# ET6801 register map
Vendor: ETMCU Inc.; File version: v0.0.1
CPU: CM7 r2p1, little endian, MPU, FPU, I-cache, D-cache, ITCM, DTCM, 4 interrupt priority bits
Registers are 32-bit, read-write, reset 0x0 unless marked. A register's access mark holds for its fields unless they carry their own. Offsets are from the block's base; [hi:lo] are bit positions.

## DAC0 — Provide an overview of the purpose and functionality of the peripheral: dacc_cfg
Base 0x40100000
Same registers: DAC1 0x40101000
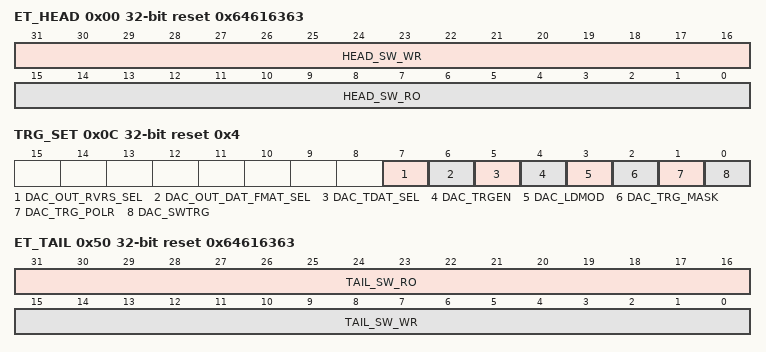
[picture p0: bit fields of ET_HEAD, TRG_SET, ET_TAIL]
0x00 ET_HEAD reset 0x64616363
  [31:16] HEAD_SW_WR — 软件测试读写寄存器，硬件无访问
  [15:0] HEAD_SW_RO ro — 软件只读上报寄存器，硬件无访问，dacc的ASICII 码表示
0x04 TDAT
  [11:0] DAC_TDAT — DAC发送数据寄存器，支持DMA更新
0x08 TRG_SEL
  [2:0] DAC_TRG_SEL — 触发启动源选择寄存器 'd0: 触发启动源选择SW配置; 'd1 : 触发启动源选择sTimer; 'd2 : 触发启动源选择eTimer; 'd3 : 触发启动源选择SuperPWM; 'd4 : 触发启动源选择tx down event; 'd5 : 未使用，接0; 'd6: 未使用，接0; 'd7 : 触发启动源选择DMA搬移完成; 默认为0，触发启动源选择SW配置。
0x0C TRG_SET reset 0x4
  [7] DAC_OUT_RVRS_SEL — dac输出数据反向选择 'd0:dac输出数据不反向，默认值； 'd1: dac输出数据反向；
  [6] DAC_OUT_DAT_FMAT_SEL — dac输出数据格式选择 'd0:偏移码输出，默认值； 'd1:补码输出；
  [5] DAC_TDAT_SEL — DAC发送数据寄存器 'd0: DAC选择从cfg_dac_tdat位域发送数据，默认值； 'd1:DAC选择从输入数据端口发送数据；
  [4] DAC_TRGEN — DAC发波启动使能控制信号寄存器 0：DAC发波不使能； 1：DAC发波使能；
  [3] DAC_LDMOD — 加载模式选择寄存器
  [2] DAC_TRG_MASK — 触发源屏蔽寄存器
  [1] DAC_TRG_POLR — 触发源极性取反寄存器
  [0] DAC_SWTRG — 软件触发寄存器，软件配置的触发源，自清0
0x10 TRG_DLY
  [7:0] DAC_TRG_DLY — 触发启动延迟寄存器，对输入的触发启动信号延迟，输出到波形产生模块。
0x14 TRG_REPT_RPT
  [0] TRG_REPT_RPT — 触发重复告警寄存器，软件写1清
0x18 TXDN_RPT
  [0] DAC_TXDN_RPT — 发波结束上报寄存器，软件写1清 注：在cfg_dac_tdat_sel =1时，即数据源来源于dacc的输入端口时，内部的数据伴随时钟将常为高，该上报寄存器也一直为1。
0x1C TXDN_REPT_RPT
  [0] DAC_TXDN_REPT_RPT — 发波结束重复脉冲告警寄存器，软件写1清 注：在cfg_dac_tdat_sel =1时，即数据源来源于dacc的输入端口时，内部的数据伴随时钟将常为高，该上报寄存器也一直为1。
0x20 TDAT ro
  [11:0] TDAT_LOAD_RPT — dac load数据上报
0x24 OS_ADJ
  [12:0] DAC_OS_ADJ — 直流失配调整寄存器
0x28 GAIN_ADJ reset 0x400
  [10:0] DAC_GAIN_ADJ — 增益误差调整寄存器
0x2C INT_MASK
  [0] DAC_INT_MASK — 中断屏蔽信号
0x30 INT_EN
  [0] DAC_INT_EN — 中断源使能信号
0x34 INT_FORCE_IND
  [0] DAC_INT_FORCE_IND — 事件中断测试寄存器，自清0寄存器
0x38 INT_CLR
  [0] DAC_INT_CLR — 中断清除寄存器，自清0寄存器
0x3C INT_RAW_RPT ro
  [0] DAC_INT_RAW_RPT — DAC发送结束事件原始中断寄存器
0x40 INT_STATUS_RPT ro
  [0] DAC_INT_STATUS_RPT — DAC发送结束事件中断状态寄存器
0x44 HDSK_EN
  [0] DAC_HDSK_EN — DAC握手模块使能信号
0x48 DONE_WH reset 0xF
  [7:0] DAC_DONE_WH — DAC发送完成事件脉冲宽度。
0x4C DMAREQ_REPT_RPT
  [0] DAC_DMAREQ_REPT_RPT — DMA请求脉冲重复告警寄存器，软件写1清
0x50 ET_TAIL reset 0x64616363
  [31:16] TAIL_SW_RO ro — 软件只读硬件上报寄存器
  [15:0] TAIL_SW_WR — 软件测试读写寄存器，硬件无访问

## WAG — Provide an overview of the purpose and functionality of the peripheral: wag_cfg
Base 0x40103000
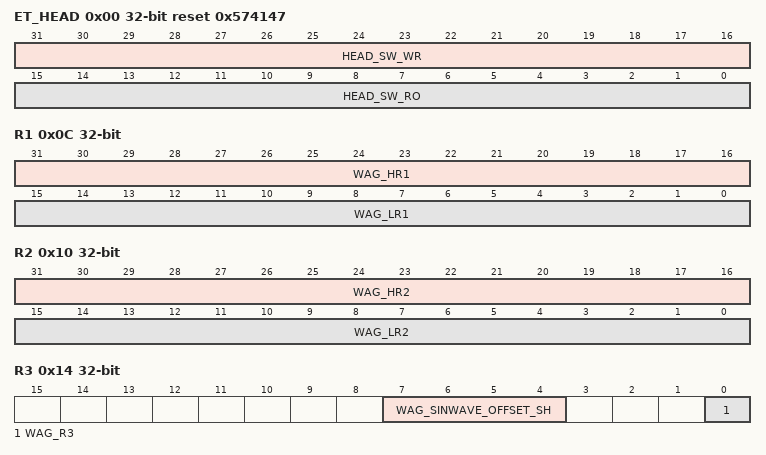
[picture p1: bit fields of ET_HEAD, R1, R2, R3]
0x00 ET_HEAD reset 0x574147
  [31:16] HEAD_SW_WR — 软件测试读写寄存器，硬件无访问
  [15:0] HEAD_SW_RO ro — 软件只读上报寄存器，硬件无访问,WAG的ASICII 码表示
0x04 CORDIC_CTRL0
  [8:4] CORDIC_NOI — CORDIC迭代周期数选择寄存器，周期数为配置值+1
0x08 R0
  [15:0] WAG_R0 — R0寄存器，触发延迟时间，使用预分频后时钟，延迟时间为：cfg_wag_r0个周期。
0x0C R1
  [31:16] WAG_HR1 — R1寄存器高16bit。 (1)RMAP波/三角波：上行幅度步进 (2)正弦波：频率控制字
  [15:0] WAG_LR1 — R1寄存器低16bit。 (1)RAMP波/三角波：下行幅度步进 (2)正弦波：初相
0x10 R2
  [31:16] WAG_HR2 — R2寄存器的高16bit (1)RMAP波/三角波：上门限值 (2)正弦波：直流幅度 (3)静态波/方波：值B
  [15:0] WAG_LR2 — R2寄存器的低16bit (1)RAMP波/三角波：下门限值 (2)正弦波：幅度调整量（仅支持1/2N幅度调整，N=0,...,12），幅度调整值需要提前除以缩放因子k，其中k为Cordic IP计算后产生的缩放因子，与计算精度相关，约为1.6 (3)静态波/方波：值A
0x14 R3
  [7:4] WAG_SINWAVE_OFFSET_SH — 正弦波幅度调整值m缩放量。即N的值
  [0] WAG_R3 — R3寄存器，用于指示R0~R2寄存器是否可加载。与cfg_wag_load_en配合使用。cfg_wag_load_en=1时，关注R3寄存器的值；当cfg_wag_load_en=0时，不关注R3寄存器的值 0x1：R0~R2已经准备好，可加载 0x0：R0~R2还未准备好，不可加载 硬件将R0~R2加载完成后，将该信号拉低 注：软件依次写入R0~R3，要将R3拉高，得先更新R0~R2
0x18 LOAD_EN reset 0x1
  [0] WAG_LOAD_EN — R0~R3是否一起加载 0x0：不要求R0~R2一致加载 0x1：要求R0~R2一致加载 注：动态寄存器，全局使能有效时可更改
0x1C RLOAD_MODE
  [0] WAG_RLOAD_MODE — R0~R3加载模式： 0x0：影子加载 0x1：立即加载 注：静态寄存器，全局使能有效时不可更改
0x20 EN
  [0] WAG_EN — 全局使能 0x0：使能 0x1：不使能
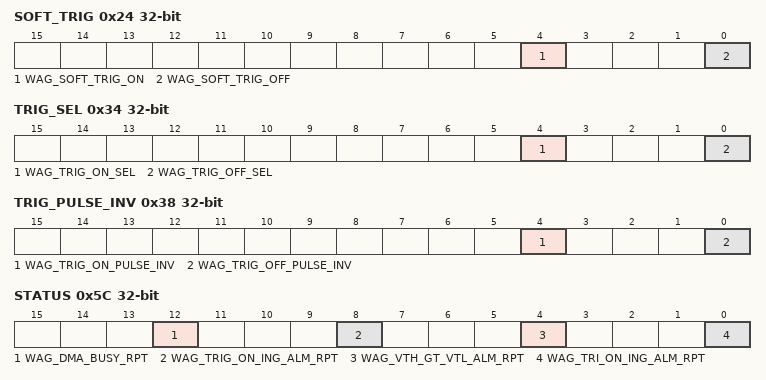
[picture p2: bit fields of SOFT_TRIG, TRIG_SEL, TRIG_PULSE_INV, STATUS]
0x24 SOFT_TRIG
  [4] WAG_SOFT_TRIG_ON — 软件启动触发 0x0：不触发 0x1：触发
  [0] WAG_SOFT_TRIG_OFF — 软件终止触发 0x0：不触发 0x1：触发
0x28 DATA_IN
  [15:0] WAG_DATA_IN — 软件保持功能模式下，软件配置码值专用寄存器 注：根据输出数据参数化位宽配置，如：输出位宽配置为12bit，则该值应该在0~4095取值
0x2C CLK_DIV_PARA reset 0xC7
  [15:0] WAG_CLK_DIV_PARA — 预分频系数，分频比为：cfg_wag_clk_div_para+1，单位为系统时钟周期 注：静态寄存器，全局使能有效时不可更改
0x30 HOLD_MODE_SEL
  [0] WAG_HOLD_MODE_SEL — 软件保持模式下，输出码值的选择 0x1：软件配置的专用寄存器码值 0x0：当前发波模式的即时值 注：静态寄存器，全局使能有效时不可更改
0x34 TRIG_SEL
  [4] WAG_TRIG_ON_SEL — 触发启动信号选择 0x0：软件触发 0x1：硬件触发 注：静态寄存器，全局使能有效时不可更改
  [0] WAG_TRIG_OFF_SEL — 触发终止信号选择 0x0：软件触发 0x1：硬件触发 注：静态寄存器，全局使能有效时不可更改
0x38 TRIG_PULSE_INV
  [4] WAG_TRIG_ON_PULSE_INV — 触发启动信号极性反转，如果输入是负脉冲，则需要极性反转；如果输入是正脉冲，则不需要极性反转 0x0：不反转 0x1：反转 注：静态寄存器，全局使能有效时不可更改
  [0] WAG_TRIG_OFF_PULSE_INV — 触发终止信号极性反转，如果输入是负脉冲，则需要极性反转；如果输入是正脉冲，则不需要极性反转 0x0：不反转 0x1：反转 注：静态寄存器，全局使能有效时不可更改
0x3C DONE_EXT reset 0xF
  [15:0] WAG_DONE_EXT — 触发完成事件脉冲扩展寄存器，单位为系统时钟，扩展周期为：cfg_wag_done_ext+1 注：静态寄存器，全局使能有效时不可更改
0x40 DMA_EN
  [0] WAG_DMA_EN — DMA握手模块使能 0x0：不产生DMA请求 0x1：产生DMA请求 注：静态寄存器，全局使能有效时不可更改
0x44 WAVE_SEL
  [2:0] WAG_WAVE_SEL — 输出波形选择： 000：静态波 001：方波 010：RAMP波 011：三角波/锯齿波 100：正弦波 default：静态波 注：静态寄存器，全局使能有效时不可更改
0x48 STAWAVE_LOAD_MODE
  [0] WAG_STAWAVE_LOAD_MODE — 静态波形模式选择： 0x0：影子加载 0x1：立即加载 注：静态寄存器，全局使能有效时不可更改
0x4C SQURWAVE_MODE
  [0] WAG_SQURWAVE_MODE — 方波发波模式选择： 0x0：非连续发波 0x1：连续发波 注：静态寄存器，全局使能有效时不可更改
0x50 RAMP_DIR
  [0] WAG_RAMP_DIR — RAMP波递增递减模式： 0x0：递减模式 0x1：递增模式 注：静态寄存器，全局使能有效时不可更改
0x54 TRIWAVE_DIR
  [0] WAG_TRIWAVE_DIR — 三角波/锯齿波起始方向： 0x0：从下门限启动 0x1：从上门限启动 注：静态寄存器，全局使能有效时不可更改
0x58 TRIWAVE_MODE
  [0] WAG_TRIWAVE_MODE — 三角波/锯齿波发波模式选择： 0x0：非连续发波 0x1：连续发波 注：静态寄存器，全局使能有效时不可更改
0x5C STATUS ro
  [12] WAG_DMA_BUSY_RPT — DMA状态指示信号 0x0：空闲 0x1：busy
  [8] WAG_TRIG_ON_ING_ALM_RPT — 在一次触发启动信号还在delay过程中，再来一个触发信号到来告警： 0x0：无告警 0x1：告警
  [4] WAG_VTH_GT_VTL_ALM_RPT — 异常情况一（下门限配置大于等于上门限）告警： 0x0：无告警 0x1：下门限>上门限
  [0] WAG_TRI_ON_ING_ALM_RPT — 异常情况五（三角波/锯齿波中，触发终止信号未被响应前，触发启动信号到来）告警： 0x0：无告警 0x1：触发启动信号被忽略
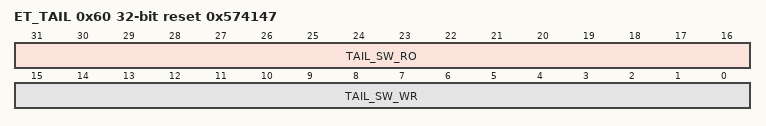
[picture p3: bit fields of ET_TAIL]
0x60 ET_TAIL reset 0x574147
  [31:16] TAIL_SW_RO ro — 软件测试读写寄存器，硬件无访问
  [15:0] TAIL_SW_WR — 软件只读上报寄存器，硬件无访问,WAG的ASICII 码表示
